VERSION ""

NS_ :

BS_:

BU_: CANoe K3

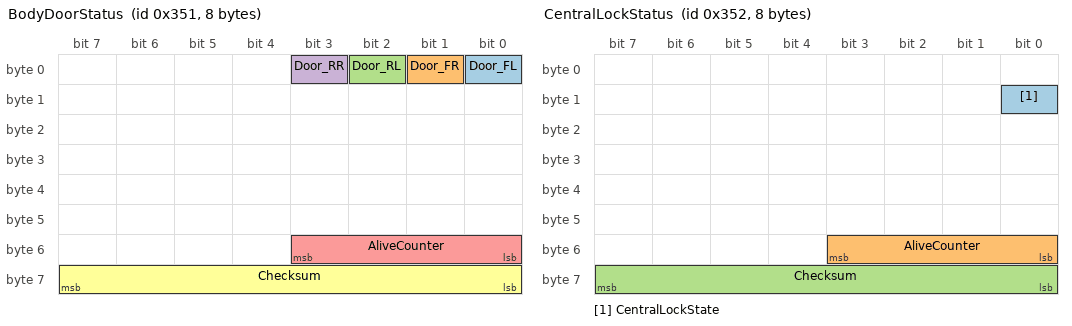
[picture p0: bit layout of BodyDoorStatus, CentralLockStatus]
BO_ 849 BodyDoorStatus: 8 CANoe
 SG_ Door_FL : 0|1@1+ (1,0) [0|1] "" K3
 SG_ Door_FR : 1|1@1+ (1,0) [0|1] "" K3
 SG_ Door_RL : 2|1@1+ (1,0) [0|1] "" K3
 SG_ Door_RR : 3|1@1+ (1,0) [0|1] "" K3
 SG_ AliveCounter : 48|4@1+ (1,0) [0|15] "" K3
 SG_ Checksum : 56|8@1+ (1,0) [0|255] "" K3

BO_ 850 CentralLockStatus: 8 CANoe
 SG_ CentralLockState : 8|1@1+ (1,0) [0|1] "" K3
 SG_ AliveCounter : 48|4@1+ (1,0) [0|15] "" K3
 SG_ Checksum : 56|8@1+ (1,0) [0|255] "" K3

VAL_ 849 Door_FL 0 "closed" 1 "open" ;
VAL_ 849 Door_FR 0 "closed" 1 "open" ;
VAL_ 849 Door_RL 0 "closed" 1 "open" ;
VAL_ 849 Door_RR 0 "closed" 1 "open" ;
VAL_ 850 CentralLockState 0 "unlocked" 1 "locked" ;
